# TC37X register map
File version: 1.0.0
CPU: CM4 r0p1, little endian, MPU, FPU, VTOR, 3 interrupt priority bits
Registers are 16-bit, read-write, reset 0x0 unless marked. A register's access mark holds for its fields unless they carry their own. Offsets are from the block's base; [hi:lo] are bit positions; {n}, {i} and the like mark numbered series.

## DOM0 — ce_dom
Base 0xF8700000
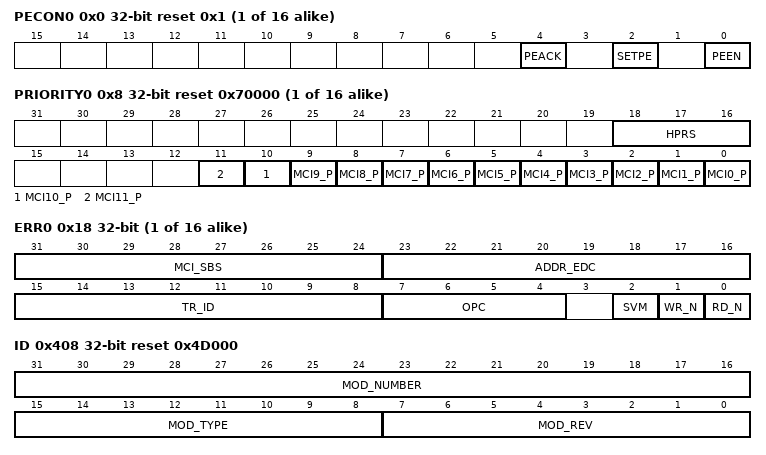
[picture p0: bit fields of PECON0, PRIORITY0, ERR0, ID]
{0x0+0x20*i} PECON{i} 32-bit reset 0x1 (i=0..15) — Protocol Error Control Register {i}
  [4] PEACK — Protocol Error Acknowledge - PEACK
  [2] SETPE — Set Protocol Error - SETPE
  [0] PEEN — Protocol Error Enable - PEEN
{0x8+0x20*i} PRIORITY{i} 32-bit reset 0x70000 (reset mask 0xFFFFF000) (i=0..15) — SCI{i} Arbiter Priority Register
  [18:16] HPRS — High Priority Round Share - HPRS
  [n] MCI{n}_P (n=0..11) — MCI{n} Priority - MCI{n}_P
{0x10+0x20*i} ERRADDR{i} 32-bit ro (i=0..15) — SCI {i} Error Address Capture Register
  [31:0] ADDR — Transaction Address - ADDR
{0x18+0x20*i} ERR{i} 32-bit ro (i=0..15) — SCI {i} Error Capture Register
  [31:24] MCI_SBS — MCI Sideband Signals [7:0] - MCI_SBS
  [23:16] ADDR_EDC — Address Phase Error Detection Information - ADDR_EDC
  [15:8] TR_ID — Transaction ID - TR_ID
  [7:4] OPC — Operation Code - OPC
  [2] SVM — Supervisor Mode Status - SVM
  [1] WR_N — Write Status - WR
  [0] RD_N — Read Status - RD
0x408 ID 32-bit ro reset 0x4D000 (reset mask 0xFFFFFF00) — Identification Register
  [31:16] MOD_NUMBER — Module Number Value - MOD_NUMBER
  [15:8] MOD_TYPE — Module Type - MOD_TYPE
  [7:0] MOD_REV — Module Revision Number - MOD_REV
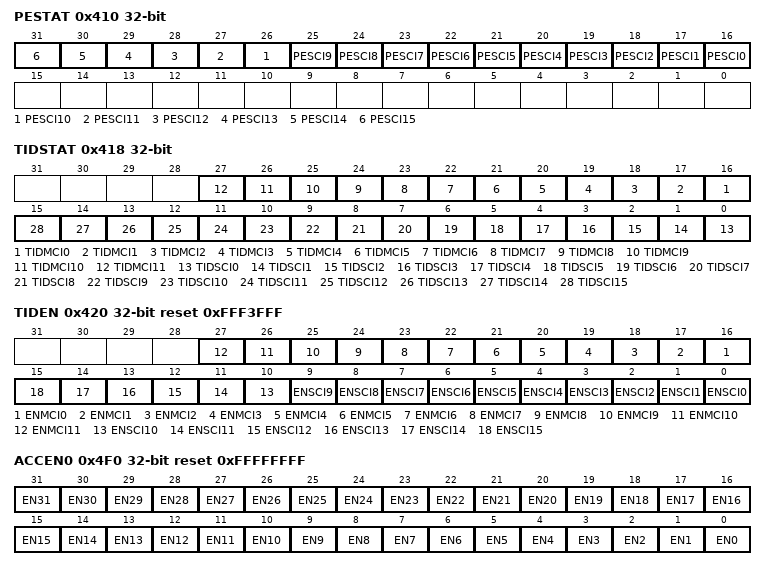
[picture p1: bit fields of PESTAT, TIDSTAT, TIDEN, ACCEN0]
0x410 PESTAT 32-bit — Protocol Error Status Register
  [n+16] PESCI{n} (n=0..15) — Protocol Error status of SCI{n} - PESCI{n}
0x418 TIDSTAT 32-bit — Transaction ID Status Register
  [n+16] TIDMCI{n} (n=0..11) — Tra{n}saction ID Error from MCIn Status - TIDMCI{n}
  [n] TIDSCI{n} (n=0..15) — Tra{n}saction ID Error from SCIn Status - TIDSCI{n}
0x420 TIDEN 32-bit reset 0xFFF3FFF — Transaction ID Enable Register
  [n+16] ENMCI{n} (n=0..11) — E{n}able Transaction ID Error from MCIn - ENMCI{n}
  [n] ENSCI{n} (n=0..15) — E{n}able Transaction ID Error from SCIn - ENSCI{n}
0x430 BRCON 32-bit reset 0x200
  [0] OLDAEN — Online Data Acquisition Enable - OLDAEN
0x4F0 ACCEN0 32-bit reset 0xFFFFFFFF — Access Enable Register 0
  [n] EN{n} (n=0..31) — Access Enable for Master TAG ID {n} - EN{n}
0x4F8 ACCEN1 32-bit ro — Access Enable Register 1

## CONVCTRL — ce_convctrl
Base 0xF0025000
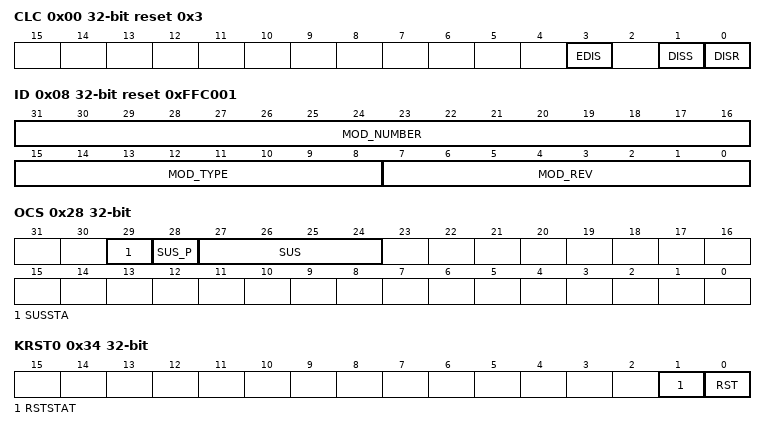
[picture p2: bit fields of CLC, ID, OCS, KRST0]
0x00 CLC 32-bit reset 0x3 — Clock Control Register
  [3] EDIS — Sleep Mode Enable Control - EDIS
  [1] DISS ro — Module Disable Status Bit - DISS
  [0] DISR — Module Disable Request Bit - DISR
0x08 ID 32-bit ro reset 0xFFC001 — Module Identification Register
  [31:16] MOD_NUMBER — Module Number - MOD_NUMBER
  [15:8] MOD_TYPE — Module Type - MOD_TYPE
  [7:0] MOD_REV — Module Revision - MOD_REV
0x28 OCS 32-bit — OCDS Control and Status Register
  [29] SUSSTA ro — Suspend State - SUSSTA
  [28] SUS_P wo — SUS Write Protection - SUS_P
  [27:24] SUS — OCDS Suspend Control - SUS
0x2C KRSTCLR 32-bit wo — Kernel Reset Status Clear Register
  [0] CLR — Kernel Reset Status Clear - CLR
0x30 KRST1 32-bit — Kernel Reset Register 1
  [0] RST — Kernel Reset - RST
0x34 KRST0 32-bit — Kernel Reset Register 0
  [1] RSTSTAT ro — Kernel Reset Status - RSTSTAT
  [0] RST — Kernel Reset - RST
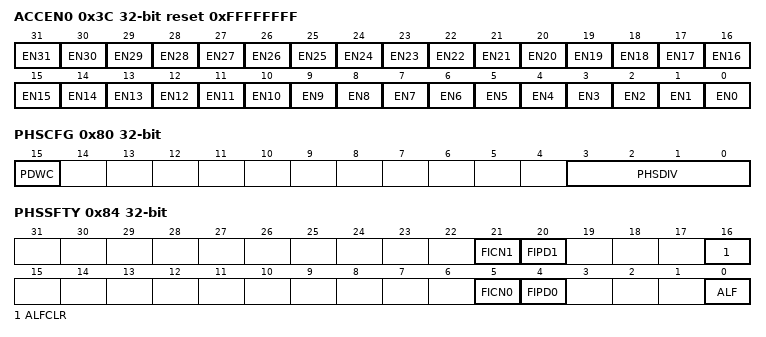
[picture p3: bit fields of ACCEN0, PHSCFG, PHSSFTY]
0x3C ACCEN0 32-bit reset 0xFFFFFFFF — Access Enable Register 0
  [n] EN{n} (n=0..31) — Access Enable for Master TAG ID {n} - EN{n}
0x7C CCCTRL 32-bit — Converter Control Block Control Register
  [31:28] TC — Test Control - TC
0x80 PHSCFG 32-bit — Phase Synchronizer Configuration Register
  [15] PDWC wo — Write Control for Phase Sync. Divider - PDWC
  [3:0] PHSDIV — Phase Synchronizer Divider - PHSDIV
0x84 PHSSFTY 32-bit — Phase Synchronizer Safety Control Register
  [21] FICN1 wo — Fault Injection Phase sync Divider
  [20] FIPD1 wo — Fault Injection Phase sync Divider
  [16] ALFCLR wo — Alarm Flag ALF Clear
  [5] FICN0 wo — Fault Injection Counter
  [4] FIPD0 wo — Fault Injection Phase sync Divider
  [0] ALF ro — Alarm Flag for Safety Features
